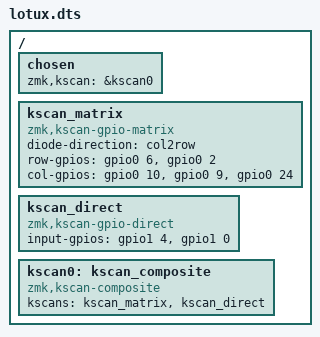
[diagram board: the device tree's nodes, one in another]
/ {
    chosen {
        zmk,kscan = &kscan0;
    };

    kscan_matrix: kscan_matrix {
        compatible = "zmk,kscan-gpio-matrix";
        diode-direction = "col2row";

        row-gpios = <
            &gpio0 6 GPIO_ACTIVE_HIGH
            &gpio0 2 GPIO_ACTIVE_HIGH
        >;

        col-gpios = <
            &gpio0 10 (GPIO_PULL_DOWN | GPIO_ACTIVE_HIGH)
            &gpio0 9  (GPIO_PULL_DOWN | GPIO_ACTIVE_HIGH)
            &gpio0 24 (GPIO_PULL_DOWN | GPIO_ACTIVE_HIGH)
        >;
    };

    kscan_direct: kscan_direct {
        compatible = "zmk,kscan-gpio-direct";

        input-gpios =
            <&gpio1 4 (GPIO_PULL_DOWN | GPIO_ACTIVE_HIGH)>,
            <&gpio1 0 (GPIO_PULL_DOWN | GPIO_ACTIVE_HIGH)>;
    };

    kscan0: kscan_composite {
        compatible = "zmk,kscan-composite";
        kscans = <&kscan_matrix &kscan_direct>;
    };
};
